# STM32G484xx register map
File version: 1.2
CPU: CM4 r0p1, little endian, MPU, FPU, 4 interrupt priority bits
Registers are 32-bit, read-write, reset 0x0 unless marked. A register's access mark holds for its fields unless they carry their own. Offsets are from the block's base; [hi:lo] are bit positions.

## SPI1 — Serial peripheral interface/Inter-IC sound
Base 0x40013000
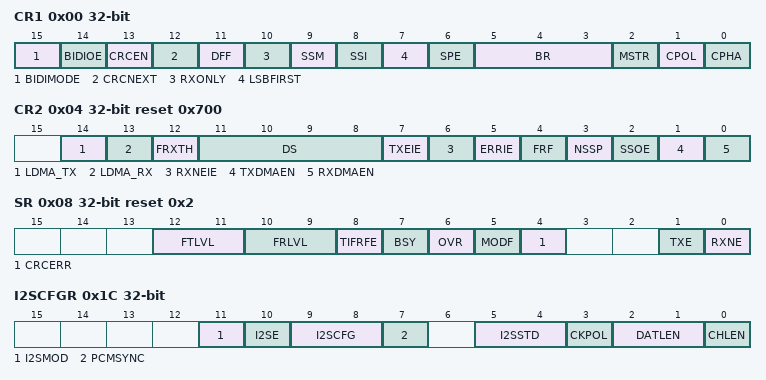
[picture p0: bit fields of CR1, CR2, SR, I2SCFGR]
0x00 CR1 — control register 1
  [15] BIDIMODE — Bidirectional data mode enable
  [14] BIDIOE — Output enable in bidirectional mode
  [13] CRCEN — Hardware CRC calculation enable
  [12] CRCNEXT — CRC transfer next
  [11] DFF — Data frame format
  [10] RXONLY — Receive only
  [9] SSM — Software slave management
  [8] SSI — Internal slave select
  [7] LSBFIRST — Frame format
  [6] SPE — SPI enable
  [5:3] BR — Baud rate control
  [2] MSTR — Master selection
  [1] CPOL — Clock polarity
  [0] CPHA — Clock phase
0x04 CR2 reset 0x700 — control register 2
  [14] LDMA_TX — Last DMA transfer for transmission
  [13] LDMA_RX — Last DMA transfer for reception
  [12] FRXTH — FIFO reception threshold
  [11:8] DS — Data size
  [7] TXEIE — Tx buffer empty interrupt enable
  [6] RXNEIE — RX buffer not empty interrupt enable
  [5] ERRIE — Error interrupt enable
  [4] FRF — Frame format
  [3] NSSP — NSS pulse management
  [2] SSOE — SS output enable
  [1] TXDMAEN — Tx buffer DMA enable
  [0] RXDMAEN — Rx buffer DMA enable
0x08 SR access per field reset 0x2 — status register
  [12:11] FTLVL ro — FIFO transmission level
  [10:9] FRLVL ro — FIFO reception level
  [8] TIFRFE ro — TI frame format error
  [7] BSY ro — Busy flag
  [6] OVR ro — Overrun flag
  [5] MODF ro — Mode fault
  [4] CRCERR rw — CRC error flag
  [1] TXE ro — Transmit buffer empty
  [0] RXNE ro — Receive buffer not empty
0x0C DR — data register
  [15:0] DR — Data register
0x10 CRCPR reset 0x7 — CRC polynomial register
  [15:0] CRCPOLY
0x14 RXCRCR ro — RX CRC register
  [15:0] RxCRC
0x18 TXCRCR ro — TX CRC register
  [15:0] TxCRC
0x1C I2SCFGR — configuration register
  [11] I2SMOD, [10] I2SE, [9:8] I2SCFG, [7] PCMSYNC, [5:4] I2SSTD, [3] CKPOL, [2:1] DATLEN, [0] CHLEN
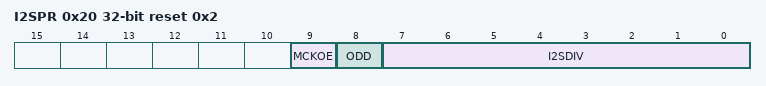
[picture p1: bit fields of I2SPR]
0x20 I2SPR reset 0x2 — prescaler register
  [9] MCKOE, [8] ODD, [7:0] I2SDIV

## SPI4 — Serial peripheral interface/Inter-IC sound
Base 0x40013C00
Same registers: SPI2 0x40003800, SPI3 0x40003C00
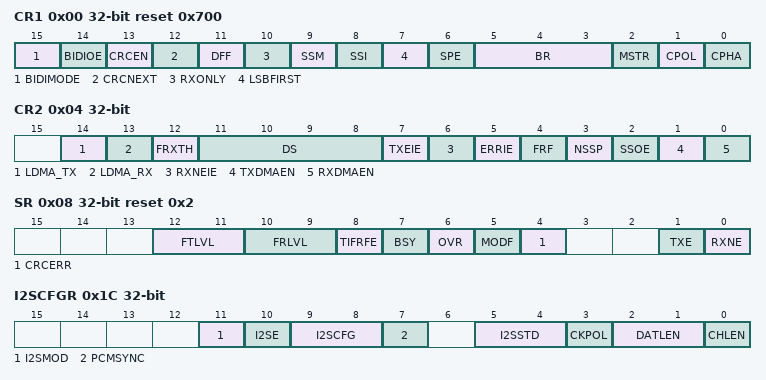
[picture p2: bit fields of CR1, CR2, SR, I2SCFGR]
0x00 CR1 reset 0x700 — control register 1
  [15] BIDIMODE — Bidirectional data mode enable
  [14] BIDIOE — Output enable in bidirectional mode
  [13] CRCEN — Hardware CRC calculation enable
  [12] CRCNEXT — CRC transfer next
  [11] DFF — Data frame format
  [10] RXONLY — Receive only
  [9] SSM — Software slave management
  [8] SSI — Internal slave select
  [7] LSBFIRST — Frame format
  [6] SPE — SPI enable
  [5:3] BR — Baud rate control
  [2] MSTR — Master selection
  [1] CPOL — Clock polarity
  [0] CPHA — Clock phase
0x04 CR2 — control register 2
  [14] LDMA_TX — Last DMA transfer for transmission
  [13] LDMA_RX — Last DMA transfer for reception
  [12] FRXTH — FIFO reception threshold
  [11:8] DS — Data size
  [7] TXEIE — Tx buffer empty interrupt enable
  [6] RXNEIE — RX buffer not empty interrupt enable
  [5] ERRIE — Error interrupt enable
  [4] FRF — Frame format
  [3] NSSP — NSS pulse management
  [2] SSOE — SS output enable
  [1] TXDMAEN — Tx buffer DMA enable
  [0] RXDMAEN — Rx buffer DMA enable
0x08 SR access per field reset 0x2 — status register
  [12:11] FTLVL ro — FIFO transmission level
  [10:9] FRLVL ro — FIFO reception level
  [8] TIFRFE ro — TI frame format error
  [7] BSY ro — Busy flag
  [6] OVR ro — Overrun flag
  [5] MODF ro — Mode fault
  [4] CRCERR rw — CRC error flag
  [1] TXE ro — Transmit buffer empty
  [0] RXNE ro — Receive buffer not empty
0x0C DR — data register
  [15:0] DR — Data register
0x10 CRCPR reset 0x7 — CRC polynomial register
  [15:0] CRCPOLY
0x14 RXCRCR ro — RX CRC register
  [15:0] RxCRC
0x18 TXCRCR ro — TX CRC register
  [15:0] TxCRC
0x1C I2SCFGR — configuration register
  [11] I2SMOD, [10] I2SE, [9:8] I2SCFG, [7] PCMSYNC, [5:4] I2SSTD, [3] CKPOL, [2:1] DATLEN, [0] CHLEN
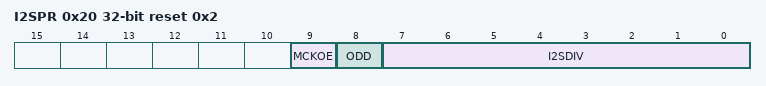
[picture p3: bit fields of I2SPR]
0x20 I2SPR reset 0x2 — prescaler register
  [9] MCKOE, [8] ODD, [7:0] I2SDIV
